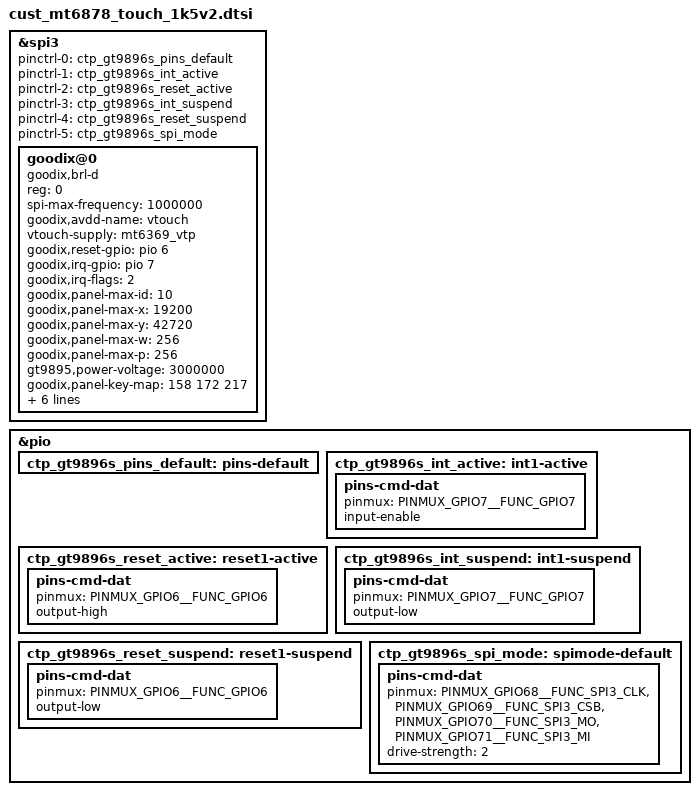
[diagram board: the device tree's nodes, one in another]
// SPDX-License-Identifier: (GPL-2.0 OR MIT)
/*
 * Copyright (C) 2020 MediaTek Inc.
 */

/* TOUCH start */

&spi3 {
	status = "okay";
	#address-cells = <1>;
	#size-cells = <0>;
	pinctrl-names = "default", "gt9896s_int_active",
		"gt9896s_reset_active", "gt9896s_int_suspend",
		"gt9896s_reset_suspend", "gt9896s_spi_mode";
	pinctrl-0 = <&ctp_gt9896s_pins_default>;
	pinctrl-1 = <&ctp_gt9896s_int_active>;
	pinctrl-2 = <&ctp_gt9896s_reset_active>;
	pinctrl-3 = <&ctp_gt9896s_int_suspend>;
	pinctrl-4 = <&ctp_gt9896s_reset_suspend>;
	pinctrl-5 = <&ctp_gt9896s_spi_mode>;

	goodix@0 {
		compatible = "goodix,brl-d";
		reg = <0>; //Same as CS ID
		spi-max-frequency = <1000000>;

		goodix,avdd-name = "vtouch";
		vtouch-supply = <&mt6369_vtp>;
		goodix,reset-gpio = <&pio 6 0x0>;
		goodix,irq-gpio = <&pio 7 0x0>;
		goodix,irq-flags = <2>; /* 1:rising, 2:falling;*/
		goodix,panel-max-id = <10>;
		goodix,panel-max-x = <19200>;
		goodix,panel-max-y = <42720>;
		goodix,panel-max-w = <256>;
		goodix,panel-max-p = <256>;
		gt9895,power-voltage = <3000000>;
		goodix,panel-key-map = <158 172 217>; /*BACK,HOMEPAGE,SEARCH*/
		goodix,power-on-delay-us = <10000>; /*10ms*/
		goodix,power-off-delay-us = <5000>;
		gt9895,firmware-name = "gt9916_vienna_firmware6878v01.bin";
		gt9895,config-name = "gt9916_vienna_cfg_6878v01.bin";
	};
};

&pio {
	ctp_gt9896s_pins_default: pins-default {
	};
	ctp_gt9896s_int_active: int1-active {
		pins-cmd-dat {
			pinmux = <PINMUX_GPIO7__FUNC_GPIO7>;
			input-enable;
		};
	};
	ctp_gt9896s_reset_active: reset1-active {
		pins-cmd-dat {
			pinmux = <PINMUX_GPIO6__FUNC_GPIO6>;
			output-high;
		};
	};
	ctp_gt9896s_int_suspend: int1-suspend {
		pins-cmd-dat {
			pinmux = <PINMUX_GPIO7__FUNC_GPIO7>;
			output-low;
		};
	};
	ctp_gt9896s_reset_suspend: reset1-suspend {
		pins-cmd-dat {
			pinmux = <PINMUX_GPIO6__FUNC_GPIO6>;
			output-low;
		};
	};
	ctp_gt9896s_spi_mode: spimode-default {
		pins-cmd-dat {
			pinmux = <PINMUX_GPIO68__FUNC_SPI3_CLK>,
				<PINMUX_GPIO69__FUNC_SPI3_CSB>,
				<PINMUX_GPIO70__FUNC_SPI3_MO>,
				<PINMUX_GPIO71__FUNC_SPI3_MI>;
			drive-strength = <2>;
		};
	};
};
/* TOUCH end */

